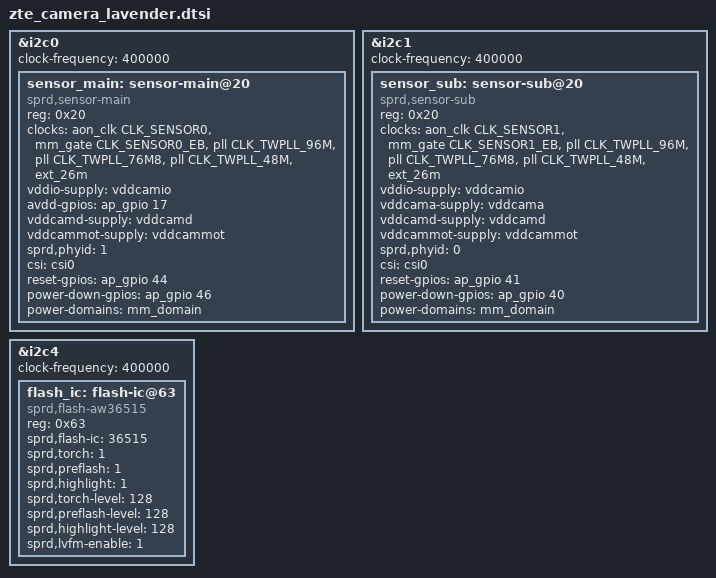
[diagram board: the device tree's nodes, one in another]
&i2c0 {
	#address-cells = <1>;
	#size-cells = <0>;

	status = "okay";
	clock-frequency = <400000>;

	sensor_main: sensor-main@20 {
		compatible = "sprd,sensor-main";
		reg = <0x20>;
		clock-names = "clk_src","sensor_eb",
			"clk_96m","clk_76m8",
			"clk_48m","clk_26m";
		clocks = <&aon_clk CLK_SENSOR0>, <&mm_gate CLK_SENSOR0_EB>,
			<&pll CLK_TWPLL_96M>,<&pll CLK_TWPLL_76M8>,
			<&pll CLK_TWPLL_48M>,<&ext_26m>;
		vddio-supply = <&vddcamio>;
		avdd-gpios = <&ap_gpio 17 0>;
		vddcamd-supply = <&vddcamd>;
		vddcammot-supply = <&vddcammot>;
		sprd,phyid = <1>;
		csi = <&csi0>;
		reset-gpios = <&ap_gpio 44 0>;
		power-down-gpios = <&ap_gpio 46 0>;
		power-domains = <&mm_domain>;
	};
};

&i2c1 {
	#address-cells = <1>;
	#size-cells = <0>;

	status = "okay";
	clock-frequency = <400000>;

	sensor_sub: sensor-sub@20 {
		compatible = "sprd,sensor-sub";
		reg = <0x20>;
		clock-names = "clk_src","sensor_eb",
			"clk_96m","clk_76m8",
			"clk_48m","clk_26m";
		clocks = <&aon_clk CLK_SENSOR1>, <&mm_gate CLK_SENSOR1_EB>,
			<&pll CLK_TWPLL_96M>,<&pll CLK_TWPLL_76M8>,
			<&pll CLK_TWPLL_48M>,<&ext_26m>;
		vddio-supply = <&vddcamio>;
		vddcama-supply = <&vddcama>;
		vddcamd-supply = <&vddcamd>;
		vddcammot-supply = <&vddcammot>;
		sprd,phyid = <0>;
		csi = <&csi0>;
		reset-gpios = <&ap_gpio 41 0>;
		power-down-gpios = <&ap_gpio 40 0>;
		power-domains = <&mm_domain>;
	};
};
&i2c4 {
	#address-cells = <1>;
	#size-cells = <0>;

	status = "okay";
	clock-frequency = <400000>;

	flash_ic: flash-ic@63 {
		compatible = "sprd,flash-aw36515";
		reg = <0x63>;
		sprd,flash-ic = <36515>;
		sprd,torch = <1>;
		sprd,preflash = <1>;
		sprd,highlight = <1>;
		sprd,torch-level = <128>;
		sprd,preflash-level = <128>;
		sprd,highlight-level = <128>;
		sprd,lvfm-enable = <1>;
	};

};
